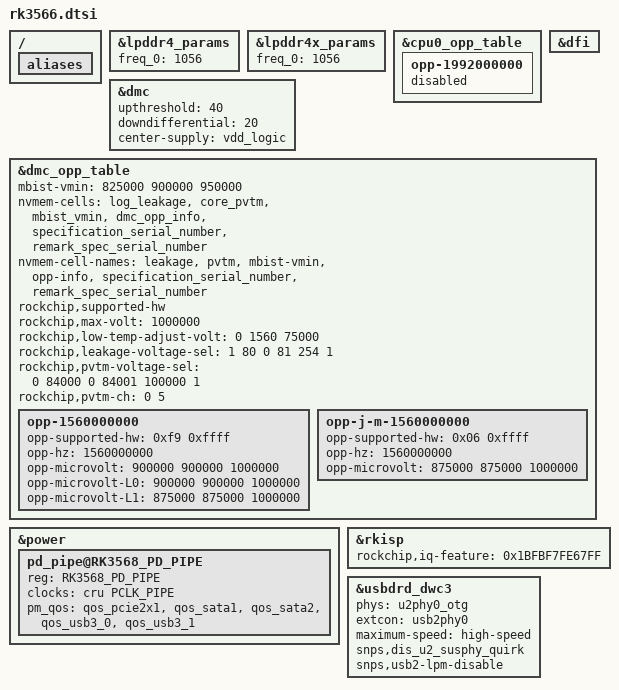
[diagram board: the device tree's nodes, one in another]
// SPDX-License-Identifier: (GPL-2.0+ OR MIT)
/*
 * Copyright (c) 2020 Rockchip Electronics Co., Ltd.
 */

#include "rk3568.dtsi"

/ {
	aliases {
		/delete-property/ ethernet0;
		/delete-property/ lvds1;
	};
};

&lpddr4_params {
	/* freq info, freq_0 is final frequency, unit: MHz */
	freq_0 = <1056>;
};

&lpddr4x_params {
	/* freq info, freq_0 is final frequency, unit: MHz */
	freq_0 = <1056>;
};

&cpu0_opp_table {
	opp-1992000000 {
		status = "disabled";
	};
};

&dfi {
	status = "okay";
};

&dmc {
	status = "okay";
	upthreshold = <40>;
	downdifferential = <20>;
	center-supply = <&vdd_logic>;
	/delete-property/ system-status-freq;
};

&dmc_opp_table {
	mbist-vmin = <825000 900000 950000>;
	nvmem-cells = <&log_leakage>, <&core_pvtm>, <&mbist_vmin>, <&dmc_opp_info>,
		      <&specification_serial_number>, <&remark_spec_serial_number>;
	nvmem-cell-names = "leakage", "pvtm", "mbist-vmin", "opp-info",
			   "specification_serial_number", "remark_spec_serial_number";
	rockchip,supported-hw;
	rockchip,max-volt = <1000000>;
	rockchip,low-temp-adjust-volt = <
		0 1560 75000
	>;
	rockchip,leakage-voltage-sel = <
		1 80 0
		81 254 1
	>;
	rockchip,pvtm-voltage-sel = <
		0     84000 0
		84001 100000 1
	>;
	rockchip,pvtm-ch = <0 5>;

	opp-1560000000 {
		opp-supported-hw = <0xf9 0xffff>;
		opp-hz = /bits/ 64 <1560000000>;
		opp-microvolt = <900000 900000 1000000>;
		opp-microvolt-L0 = <900000 900000 1000000>;
		opp-microvolt-L1 = <875000 875000 1000000>;
	};

	opp-j-m-1560000000 {
		opp-supported-hw = <0x06 0xffff>;
		opp-hz = /bits/ 64 <1560000000>;
		opp-microvolt = <875000 875000 1000000>;
	};
};

&power {
	pd_pipe@RK3568_PD_PIPE {
		reg = <RK3568_PD_PIPE>;
		clocks = <&cru PCLK_PIPE>;
		pm_qos = <&qos_pcie2x1>,
			 <&qos_sata1>,
			 <&qos_sata2>,
			 <&qos_usb3_0>,
			 <&qos_usb3_1>;
	};
};

&rkisp {
	rockchip,iq-feature = /bits/ 64 <0x1BFBF7FE67FF>;
};

&usbdrd_dwc3 {
	phys = <&u2phy0_otg>;
	phy-names = "usb2-phy";
	extcon = <&usb2phy0>;
	maximum-speed = "high-speed";
	snps,dis_u2_susphy_quirk;
	snps,usb2-lpm-disable;
};

/delete-node/ &combphy0_us;
/delete-node/ &gmac0_clkin;
/delete-node/ &gmac0_xpcsclk;
/delete-node/ &gmac0;
/delete-node/ &gmac_uio0;
/delete-node/ &lvds1;
/delete-node/ &pcie30_phy_grf;
/delete-node/ &pcie30phy;
/delete-node/ &pcie3x1;
/delete-node/ &pcie3x2;
/delete-node/ &qos_pcie3x1;
/delete-node/ &qos_pcie3x2;
/delete-node/ &qos_sata0;
/delete-node/ &sata0;
/delete-node/ &vp1_out_lvds1;
/delete-node/ &vp2_out_lvds1;
